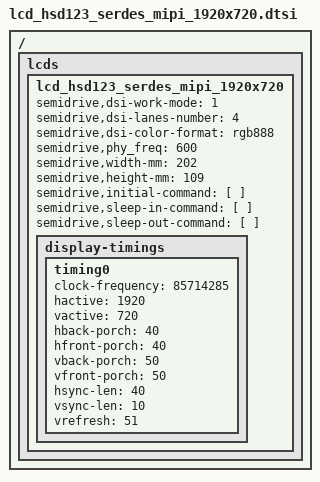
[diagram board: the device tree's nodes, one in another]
/ { lcds {
	lcd_hsd123_serdes_mipi_1920x720: lcd_hsd123_serdes_mipi_1920x720 {

		semidrive,dsi-work-mode = <1>; /* video burst mode*/
		semidrive,dsi-lanes-number = <4>;
		semidrive,dsi-color-format = "rgb888";

		semidrive,phy_freq = <600>;  /* Mbps */

		semidrive,width-mm = <202>;
		semidrive,height-mm = <109>;

		semidrive,initial-command = [
			];

		semidrive,sleep-in-command = [
			];
		semidrive,sleep-out-command = [
			];

		display-timings {
			timing0 {
				clock-frequency = <85714285>;
				hactive = <1920>;
				vactive = <720>;
				hback-porch = <40>;
				hfront-porch = <40>;
				vback-porch = <50>;
				vfront-porch = <50>;
				hsync-len = <40>;
				vsync-len = <10>;
				vrefresh = <51>;
			};
		};
	};
};};
